# cc13x2_cc26x2 register map
File version: 2.1
CPU: CM4 r0p1, little endian, MPU, FPU, 3 interrupt priority bits
Registers are 32-bit, read-write, reset 0x0 unless marked. A register's access mark holds for its fields unless they carry their own. Offsets are from the block's base; [hi:lo] are bit positions; {n}, {i} and the like mark numbered series.

## AON_IOC — Always On (AON) IO Controller - controls IO operation when the MCU IO Controller (IOC) is powered off and resides in the AON domain. Note: This module only supports 32 bit Read/Write access from MCU.
Base 0x40094000
0x00 IOSTRMIN reset 0x3 — Internal. Only to be used through TI provided API.
  [2:0] GRAY_CODE
0x04 IOSTRMED reset 0x6 — Internal. Only to be used through TI provided API.
  [2:0] GRAY_CODE
0x08 IOSTRMAX reset 0x5 — Internal. Only to be used through TI provided API.
  [2:0] GRAY_CODE
0x10 CLK32KCTL reset 0x1 — SCLK_LF External Output Control
  [0] OE_N
0x14 TCKCTL reset 0x1 — TCK IO Pin Control
  [0] EN

## AON_PMCTL — This component control the Power Management controller residing in the AON domain. ote: This module is only supporting 32 bit Read Write access from MCU
Base 0x40090000
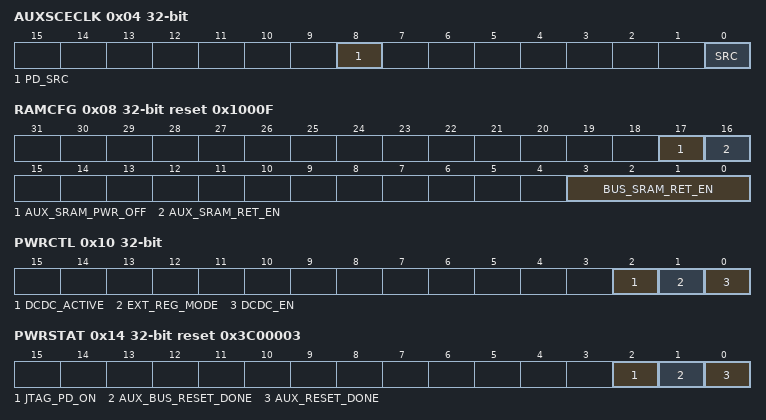
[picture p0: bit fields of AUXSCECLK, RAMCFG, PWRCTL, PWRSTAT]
0x04 AUXSCECLK — AUX SCE Clock Management his register contains bitfields that are relevant for setting up the clock to the AUX domain.
  [8] PD_SRC, [0] SRC
0x08 RAMCFG reset 0x1000F — RAM Configuration his register contains power management related configuration for the SRAM in the MCU and AUX domain.
  [17] AUX_SRAM_PWR_OFF, [16] AUX_SRAM_RET_EN, [3:0] BUS_SRAM_RET_EN
0x10 PWRCTL — Power Management Control his register controls bitfields for setting low level power management features such as selection of regulator for VDDR supply and control of IO ring where certain segments can be enabled / disabled.
  [2] DCDC_ACTIVE, [1] EXT_REG_MODE, [0] DCDC_EN
0x14 PWRSTAT reset 0x3C00003 — AON Power and Reset Status his register is used to monitor various power management related signals in AON. All other signals than JTAG_PD_ON, AUX_BUS_RESET_DONE, and AUX_RESET_DONE are for test, calibration and debug purpose only.
  [2] JTAG_PD_ON, [1] AUX_BUS_RESET_DONE, [0] AUX_RESET_DONE
0x18 SHUTDOWN — Shutdown Control his register contains bitfields required for entering shutdown mode
  [0] EN
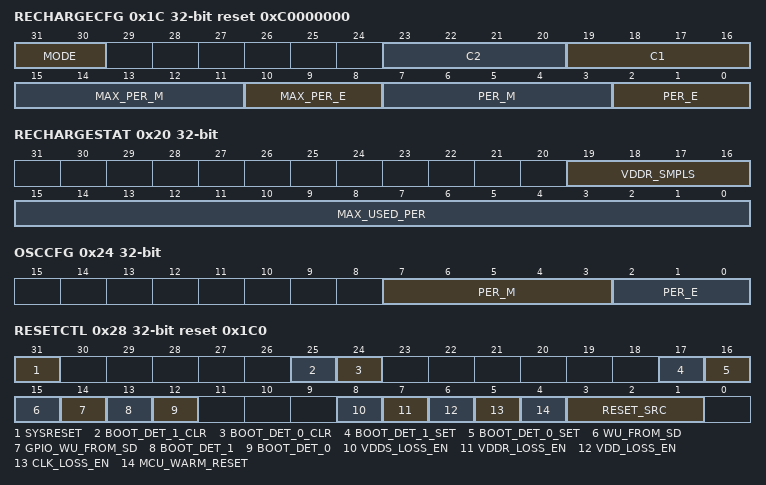
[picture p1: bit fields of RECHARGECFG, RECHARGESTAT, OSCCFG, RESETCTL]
0x1C RECHARGECFG reset 0xC0000000 — Recharge Controller Configuration his register sets all relevant parameters for controlling the recharge algorithm.
  [31:30] MODE, [23:20] C2, [19:16] C1, [15:11] MAX_PER_M, [10:8] MAX_PER_E, [7:3] PER_M, [2:0] PER_E
0x20 RECHARGESTAT — Recharge Controller Status his register controls various status registers which are updated during recharge. The register is mostly intended for test and debug.
  [19:16] VDDR_SMPLS, [15:0] MAX_USED_PER
0x24 OSCCFG — Oscillator Configuration his register sets the period for Amplitude compensation requests sent to the oscillator control system. The amplitude compensations is only applicable when XOSC_HF is running in low power mode.
  [7:3] PER_M, [2:0] PER_E
0x28 RESETCTL reset 0x1C0 — Reset Management his register contains bitfields related to system reset such as reset source and reset request and control of brown out resets.
  [31] SYSRESET, [25] BOOT_DET_1_CLR, [24] BOOT_DET_0_CLR, [17] BOOT_DET_1_SET, [16] BOOT_DET_0_SET, [15] WU_FROM_SD, [14] GPIO_WU_FROM_SD, [13] BOOT_DET_1, [12] BOOT_DET_0, [8] VDDS_LOSS_EN, [7] VDDR_LOSS_EN, [6] VDD_LOSS_EN, [5] CLK_LOSS_EN, [4] MCU_WARM_RESET write-1-clears, [3:1] RESET_SRC
0x2C SLEEPCTL — Sleep Control his register is used to unfreeze the IO pad ring after waking up from SHUTDOWN
  [0] IO_PAD_SLEEP_DIS
0x34 JTAGCFG reset 0x100 — JTAG Configuration his register contains control for configuration of the JTAG domain. This includes permissions for each TAP.
  [8] JTAG_PD_FORCE_ON
0x3C JTAGUSERCODE reset 0xB99A02F — JTAG USERCODE oot code copies the JTAG USERCODE to this register from where it is forwarded to the debug subsystem.
  [31:0] USER_CODE

## AON_RTC — This component control the Real Time Clock residing in AON ote: This module is only supporting 32 bit ReadWrite access.
Base 0x40092000
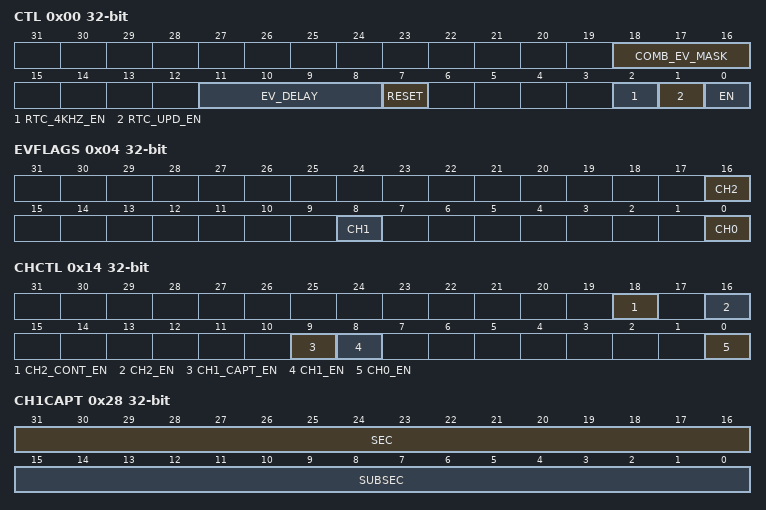
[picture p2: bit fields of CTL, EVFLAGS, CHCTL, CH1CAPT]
0x00 CTL — Control his register contains various bitfields for configuration of RTC TL Name = CONFIG
  [18:16] COMB_EV_MASK, [11:8] EV_DELAY, [7] RESET write-1-clears, [2] RTC_4KHZ_EN, [1] RTC_UPD_EN, [0] EN
0x04 EVFLAGS — Event Flags, RTC Status his register contains event flags from the 3 RTC channels. Each flag will be cleared when writing a '1' to the corresponding bitfield.
  [16] CH2 write-1-clears, [8] CH1 write-1-clears, [0] CH0 write-1-clears
0x08 SEC — Second Counter Value, Integer Part
  [31:0] VALUE
0x0C SUBSEC — Second Counter Value, Fractional Part
  [31:0] VALUE
0x10 SUBSECINC ro reset 0x800000 — Subseconds Increment alue added to SUBSEC.VALUE on every SCLK_LFclock cycle.
  [23:0] VALUEINC
0x14 CHCTL — Channel Configuration
  [18] CH2_CONT_EN, [16] CH2_EN, [9] CH1_CAPT_EN, [8] CH1_EN, [0] CH0_EN
{0x18+4i} CH{i}CMP (i=0..2) — Channel {i} Compare Value
  [31:0] VALUE
0x24 CH2CMPINC — Channel 2 Compare Value Auto-increment his register is primarily used to generate periodical wake-up for the AUX_SCE module, through the [AUX_EVCTL.EVSTAT0.AON_RTC] event.
  [31:0] VALUE
0x28 CH1CAPT ro — Channel 1 Capture Value f CHCTL.CH1_EN = 1and CHCTL.CH1_CAPT_EN = 1, capture occurs on each rising edge of the event selected in AON_EVENT:RTCSEL.
  [31:16] SEC, [15:0] SUBSEC
0x2C SYNC — AON Synchronization his register is used for synchronizing between MCU and entire AON domain.
  [0] WBUSY
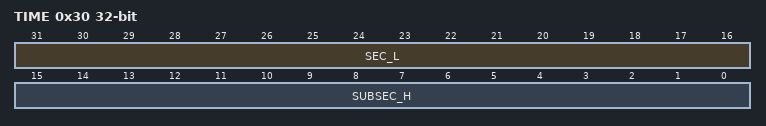
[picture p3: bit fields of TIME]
0x30 TIME ro — Current Counter Value
  [31:16] SEC_L, [15:0] SUBSEC_H
0x34 SYNCLF ro — Synchronization to SCLK_LF his register is used for synchronizing MCU to positive or negative edge of SCLK_LF.
  [0] PHASE
